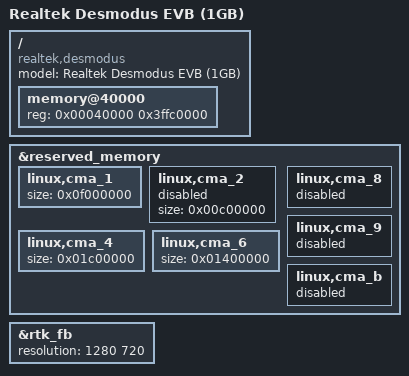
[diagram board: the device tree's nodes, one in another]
// SPDX-License-Identifier: (GPL-2.0-or-later OR BSD-2-Clause)
/*
 * Copyright (c) 2023 Realtek Semiconductor Corp.
 */

/dts-v1/;

#include "rtd1325-desmodus.dtsi"

/ {
	compatible = "realtek,desmodus", "realtek,rtd1325";
	model = "Realtek Desmodus EVB (1GB)";

	memory@40000 {
		device_type = "memory";
		reg = <0x00040000 0x3ffc0000>; /* 1 GB */
	};
};

&reserved_memory {
	linux,cma_1 {
		size = <0x0f000000>;		/* VO: 160MB + 66MB(gen) + extra*/
	};

	linux,cma_2 {
		size = <0x00c00000>;		/* TP: 10MB + 2MB(aligned) */
		status = "disabled";            /* TP: Disabled */
	};

	linux,cma_4 {
		size = <0x01c00000>;		/* VIDEO: 28MB */
	};

	linux,cma_6 {
		size = <0x01400000>;		/* OTA: 20MB */
	};

	linux,cma_8 {
		status = "disabled";
	};

	linux,cma_9 {
		status = "disabled";
	};

	linux,cma_b {
		status = "disabled";
	};
};

&rtk_fb {
	resolution = <1280 720>;
};
